AUTOSAR XML (schema 4-2-2)
package /Components
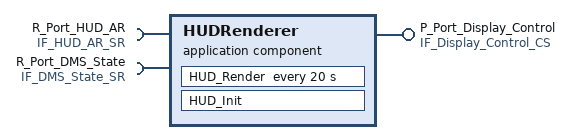
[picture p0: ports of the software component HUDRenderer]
  application sw component type HUDRenderer
    provide port P_Port_Display_Control: provided-interface=IF_Display_Control_CS
    require port R_Port_HUD_AR: required-interface=IF_HUD_AR_SR
    require port R_Port_DMS_State: required-interface=IF_DMS_State_SR
    behavior HUDRenderer_InternalBehavior
      data received event HUD_Frame_Received: start-on-event=HUD_Render
      init event HUD_Init_Event: start-on-event=HUD_Init
      timing event HUD_Render_Tick: start-on-event=HUD_Render, period=20
      runnable HUD_Init
        data-read-access:
          access VA_Init_Read_DMS_Timestamp: accessed-variable=R_Port_DMS_State.Timestamp
        data-receive-point-by-arguments:
          access VA_Init_Receive_HUD_Timestamp: accessed-variable=R_Port_HUD_AR.Timestamp
        parameter access PA_Load_HUD_Calibration: accessed-parameter=R_Port_HUD_AR.Timestamp
        parameter access PA_Load_Brightness_Default: accessed-parameter=P_Port_Display_Control.Theme_Id
      runnable HUD_Render
        data-read-access:
          4 x access:
            VA_Read_DMS_Attention: accessed-variable=R_Port_DMS_State.Driver_Attention
            VA_Read_DMS_Drowsiness: accessed-variable=R_Port_DMS_State.Drowsiness_Level
            VA_Read_DMS_EyesOffRoad: accessed-variable=R_Port_DMS_State.Eyes_Off_Road
            VA_Read_DMS_Timestamp: accessed-variable=R_Port_DMS_State.Timestamp
        data-receive-point-by-arguments:
          access VA_Receive_HUD_Frame: accessed-variable=R_Port_HUD_AR.HUD_Frame
          access VA_Receive_AR_Nav_Overlay: accessed-variable=R_Port_HUD_AR.AR_Nav_Overlay
          access VA_Receive_HUD_Timestamp: accessed-variable=R_Port_HUD_AR.Timestamp
        parameter access PA_Render_Read_Brightness: accessed-parameter=P_Port_Display_Control.Theme_Id
